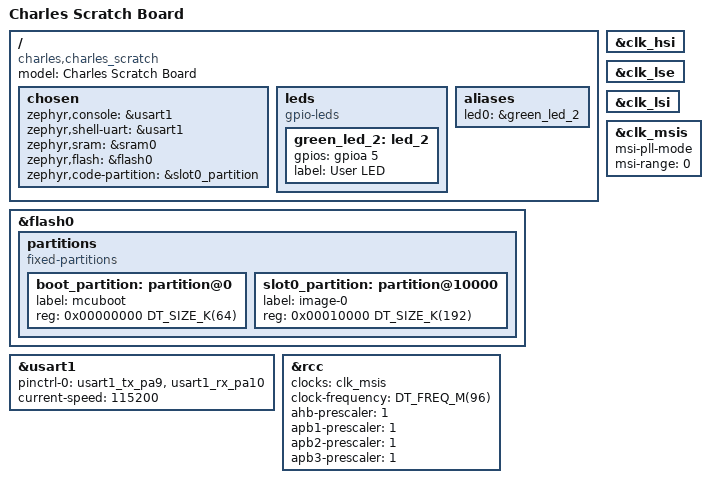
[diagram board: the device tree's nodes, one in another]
/*
 * Charles' scratch board from stm32u385rgtxq.
 */
/dts-v1/;
#include <st/u3/stm32u385Xg.dtsi>
#include <st/u3/stm32u385rgtxq-pinctrl.dtsi>
#include <zephyr/dt-bindings/input/input-event-codes.h>
/{
	model = "Charles Scratch Board";
	compatible = "charles,charles_scratch";

	chosen {
		zephyr,console = &usart1;
		zephyr,shell-uart = &usart1;
		zephyr,sram = &sram0;
		zephyr,flash = &flash0;
		zephyr,code-partition = &slot0_partition;
	};

	leds: leds {
		compatible = "gpio-leds";
		
		green_led_2: led_2 {
			gpios = <&gpioa 5 GPIO_ACTIVE_HIGH>;
			label = "User LED";
		};
	};
	
	aliases {
		led0 = &green_led_2;
	};
};

&flash0 {
	partitions {
		compatible = "fixed-partitions";
		#address-cells = <1>;
		#size-cells = <1>;

		boot_partition: partition@0 {
			label = "mcuboot";
			reg = <0x00000000 DT_SIZE_K(64)>;
		};

		slot0_partition: partition@10000 {
			label = "image-0";
			reg = <0x00010000 DT_SIZE_K(192)>;
		};

	};
};

&usart1 {
	pinctrl-0 = <&usart1_tx_pa9 &usart1_rx_pa10>;
	pinctrl-names = "default";
	current-speed = <115200>;
	status = "okay";
};

&clk_hsi {
	status = "okay";
};

&clk_lse {
	status = "okay";
};

&clk_lsi {
	status = "okay";
};

&clk_msis {
	status = "okay";
        msi-pll-mode;
        msi-range = <0>; /* 96MHz (reset value) */
};

&rcc {
	clocks = <&clk_msis>;
	clock-frequency = <DT_FREQ_M(96)>;
	ahb-prescaler = <1>;
	apb1-prescaler = <1>;
	apb2-prescaler = <1>;
	apb3-prescaler = <1>;

};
